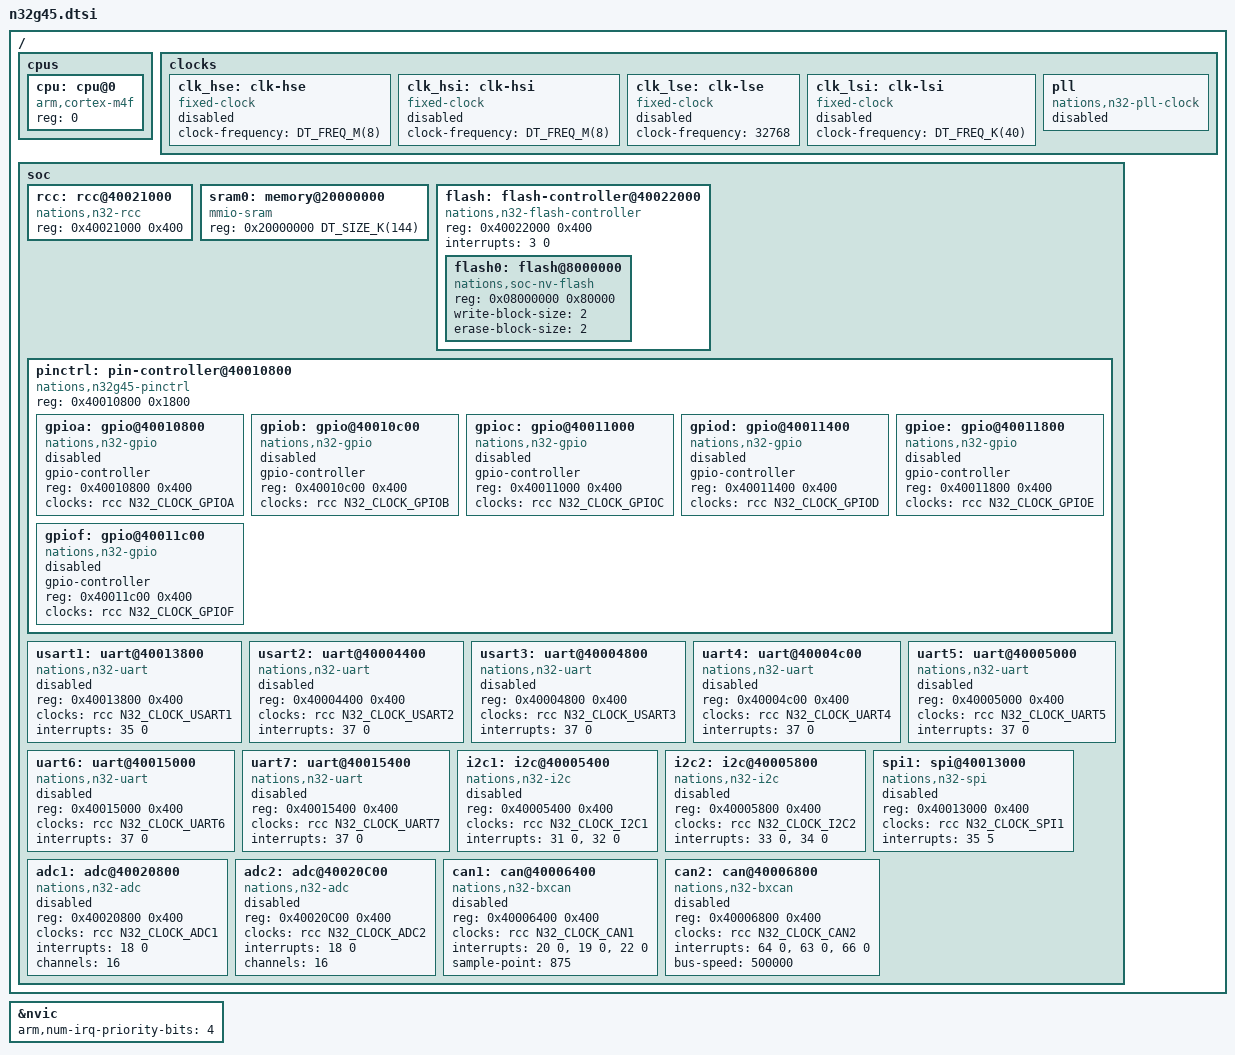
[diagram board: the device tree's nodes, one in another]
#include <mem.h>
#include <freq.h>
#include <arm/armv7-m.dtsi>
#include <zephyr/dt-bindings/gpio/gpio.h>
#include <zephyr/dt-bindings/clock/n32_clock.h>

/ {
    cpus {
        #address-cells = <1>;
        #size-cells = <0>;

        cpu: cpu@0 {
            device_type = "cpu";
            compatible = "arm,cortex-m4f";
            reg = <0>;
        };
    };
    



    clocks {
        clk_hse: clk-hse {
            #clock-cells = <0>;
            compatible = "fixed-clock";
            clock-frequency = <DT_FREQ_M(8)>;
            status = "disabled";
        };

        clk_hsi: clk-hsi {
            #clock-cells = <0>;
            compatible = "fixed-clock";
            clock-frequency = <DT_FREQ_M(8)>;
            status = "disabled";
        };

        clk_lse: clk-lse {
            #clock-cells = <0>;
            compatible = "fixed-clock";
            clock-frequency = <32768>;
            status = "disabled";
        };

        clk_lsi: clk-lsi {
            #clock-cells = <0>;
            compatible = "fixed-clock";
            clock-frequency = <DT_FREQ_K(40)>;
            status = "disabled";
        };

        pll: pll {
            #clock-cells = <0>;
            compatible = "nations,n32-pll-clock";
            status = "disabled";
        };
    };

    soc {

    
        rcc: rcc@40021000  {
            compatible = "nations,n32-rcc";
            #clock-cells = <1>;
            reg = <0x40021000 0x400>;
       };
        
        sram0: memory@20000000 {
            compatible = "mmio-sram";
            reg = <0x20000000 DT_SIZE_K(144)>;
        };

        flash: flash-controller@40022000 {
            compatible = "nations,n32-flash-controller";
            reg = <0x40022000 0x400>;
            interrupts = <3 0>;
            #address-cells = <1>;
            #size-cells = <1>;

            flash0: flash@8000000 {
                compatible = "nations,soc-nv-flash";
                reg = <0x08000000 0x80000>;
                write-block-size = <2>;
                erase-block-size = <2>;
            };    
        };
    
        pinctrl: pin-controller@40010800 {
            compatible = "nations,n32g45-pinctrl";
            reg = <0x40010800 0x1800>;
            #address-cells = <1>;
            #size-cells = <1>;

            gpioa: gpio@40010800 {
                compatible = "nations,n32-gpio";
                gpio-controller;
                #gpio-cells = <2>;
                reg = <0x40010800 0x400>;
                clocks = <&rcc N32_CLOCK_GPIOA>;
                status = "disabled";
                
            };

            gpiob: gpio@40010c00 {
                compatible = "nations,n32-gpio";
                gpio-controller;
                #gpio-cells = <2>;
                reg = <0x40010c00 0x400>;
                clocks = <&rcc N32_CLOCK_GPIOB>;
                status = "disabled";
            };

            gpioc: gpio@40011000 {
                compatible = "nations,n32-gpio";
                gpio-controller;
                #gpio-cells = <2>;
                reg = <0x40011000 0x400>;
                clocks = <&rcc N32_CLOCK_GPIOC>;
                status = "disabled";
            };

            gpiod: gpio@40011400 {
                compatible = "nations,n32-gpio";
                gpio-controller;
                #gpio-cells = <2>;
                reg = <0x40011400 0x400>;
                clocks = <&rcc N32_CLOCK_GPIOD>;
                status = "disabled";
            };

            gpioe: gpio@40011800 {
                compatible = "nations,n32-gpio";
                gpio-controller;
                #gpio-cells = <2>;
                reg = <0x40011800 0x400>;
                clocks = <&rcc N32_CLOCK_GPIOE>;
                status = "disabled";
            };

            gpiof: gpio@40011c00 {
                compatible = "nations,n32-gpio";
                gpio-controller;
                #gpio-cells = <2>;
                reg = <0x40011c00 0x400>;
                clocks = <&rcc N32_CLOCK_GPIOF>;
                status = "disabled";
            };
        };
      

        
        
        
        
        usart1: uart@40013800 {
            compatible = "nations,n32-uart";
            reg = <0x40013800 0x400>;
            clocks = <&rcc N32_CLOCK_USART1 >;
            interrupts = <35 0>;
            status = "disabled";
        };
        
        usart2: uart@40004400 {
            compatible = "nations,n32-uart";
            reg = <0x40004400 0x400>;
            clocks = <&rcc N32_CLOCK_USART2>;
            interrupts = <37 0>;
            status = "disabled";
        };

        usart3: uart@40004800 {
            compatible = "nations,n32-uart";
            reg = <0x40004800 0x400>;
            clocks = <&rcc N32_CLOCK_USART3>;
            interrupts = <37 0>;
            status = "disabled";
        };

        uart4: uart@40004c00 {
            compatible = "nations,n32-uart";
            reg = <0x40004c00 0x400>;
            clocks = <&rcc N32_CLOCK_UART4>;
            interrupts = <37 0>;
            status = "disabled";
        };

        uart5: uart@40005000 {
            compatible = "nations,n32-uart";
            reg = <0x40005000 0x400>;
            clocks = <&rcc N32_CLOCK_UART5>;
            interrupts = <37 0>;
            status = "disabled";
        };

        uart6: uart@40015000 {
            compatible = "nations,n32-uart";
            reg = <0x40015000 0x400>;
            clocks = <&rcc N32_CLOCK_UART6>;
            interrupts = <37 0>;
            status = "disabled";
        };

        uart7: uart@40015400 {
            compatible = "nations,n32-uart";
            reg = <0x40015400 0x400>;
            clocks = <&rcc N32_CLOCK_UART7>;
            interrupts = <37 0>;
            status = "disabled";
        };
        
        
        i2c1: i2c@40005400 {
            compatible = "nations,n32-i2c";

            #address-cells = <1>;
            #size-cells = <0>;
            reg = <0x40005400 0x400>;
            clocks = <&rcc N32_CLOCK_I2C1 >;
            interrupts = <31 0>, <32 0>;
            interrupt-names = "event", "error";
            status = "disabled";
        };
        
        i2c2: i2c@40005800 {
            compatible = "nations,n32-i2c";
       
            #address-cells = <1>;
            #size-cells = <0>;
            reg = <0x40005800 0x400>;
            clocks = <&rcc N32_CLOCK_I2C2 >;
            interrupts = <33 0>, <34 0>;
            interrupt-names = "event", "error";
            status = "disabled";
        };
        
        spi1: spi@40013000 {
			compatible = "nations,n32-spi";
			#address-cells = <1>;
			#size-cells = <0>;
			reg = <0x40013000 0x400>;
			clocks = <&rcc N32_CLOCK_SPI1>;
			interrupts = <35 5>;
			status = "disabled";
		};
        
        adc1: adc@40020800 {
			compatible = "nations,n32-adc";
			reg = <0x40020800 0x400>;
			clocks = <&rcc N32_CLOCK_ADC1>;
			interrupts = <18 0>;

			#io-channel-cells = <1>;
            channels = <16>;
            status = "disabled";
		};
        
        adc2: adc@40020C00 {
			compatible = "nations,n32-adc";
			reg = <0x40020C00 0x400>;
			clocks = <&rcc N32_CLOCK_ADC2>;
			interrupts = <18 0>;

			#io-channel-cells = <1>;
            channels = <16>;
            status = "disabled";
		};
        
        
        can1: can@40006400 {
			compatible = "nations,n32-bxcan";
			reg = <0x40006400 0x400>;
			clocks = <&rcc N32_CLOCK_CAN1>;
             
            interrupts = <20 0>, <19 0>, <22 0>;
            interrupt-names = "rx", "tx", "sce";
			sample-point = <875>;
			#io-channel-cells = <1>;
            status = "disabled";
		};

        can2: can@40006800 {
			compatible = "nations,n32-bxcan";
			reg = <0x40006800 0x400>;
			clocks = <&rcc N32_CLOCK_CAN2>;
            interrupts = <64 0>, <63 0>, <66 0>;
            
			bus-speed = <500000>;
			#io-channel-cells = <1>;
            status = "disabled";
        };
        
    };
};

&nvic {
    arm,num-irq-priority-bits = <4>;
};

